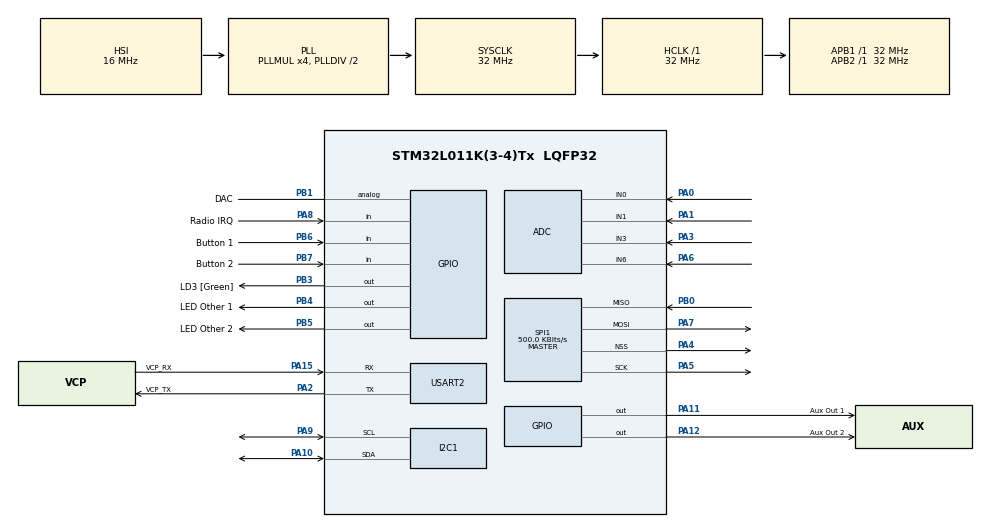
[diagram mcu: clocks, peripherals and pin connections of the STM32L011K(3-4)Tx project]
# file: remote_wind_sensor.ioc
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Mcu.Family=STM32L0
PA6.Mode=IN6
SPI1.VirtualType=VM_MASTER
PA14.GPIO_Label=TCK
PB6.GPIO_Label=Button 1
RCC.SYSCLKSource=RCC_SYSCLKSOURCE_PLLCLK
ProjectManager.StackSize=0x400
PA15.GPIO_Label=VCP_RX
PA12.Signal=GPIO_Output
PA4.Mode=NSS_Signal_Hard_Output
SPI1.Direction=SPI_DIRECTION_2LINES
RCC.HCLKFreq_Value=32000000
RCC.APB2TimFreq_Value=32000000
PB6.Signal=GPIO_Input
SPI1.CalculateBaudRate=500.0 KBits/s
RCC.AHBFreq_Value=32000000
RCC.HSE_VALUE=8000000
USART2.VirtualMode-Asynchronous=VM_ASYNC
PA15.Mode=Asynchronous
RCC.PLLMUL=RCC_PLLMUL_4
PA0-CK_IN.Signal=ADC_IN0
PC14-OSC32_IN.Mode=LSE-External-Oscillator
PA14.Mode=Serial_Wire
PB1.GPIO_Label=DAC
PB7.Signal=GPIO_Input
PA8.Signal=GPIO_Input
SPI1.VirtualNSS=VM_NSSHARD
PB7.GPIO_Label=Button 2
Mcu.Package=LQFP32
PB1.Signal=GPIO_Analog
PA6.Signal=ADC_IN6
PA2.GPIO_Label=VCP_TX
PA10.Signal=I2C1_SDA
PA15.Signal=USART2_RX
PB5.GPIO_Label=LED Other 2
RCC.APB1TimFreq_Value=32000000
SPI1.BaudRatePrescaler=SPI_BAUDRATEPRESCALER_64
RCC.HSI48_VALUE=48000000
PB4.Signal=GPIO_Output
PA3.Signal=ADC_IN3
PA5.Mode=Full_Duplex_Master
PB3.GPIO_Label=LD3 [Green]
RCC.MSI_VALUE=2097000
PC15-OSC32_OUT.Mode=LSE-External-Oscillator
PA7.Mode=Full_Duplex_Master
PA10.Mode=I2C
PA0-CK_IN.Mode=IN0
PA11.GPIO_Label=Aux Out 1
PC14-OSC32_IN.Signal=RCC_OSC32_IN
ADC.ClockPrescaler=ADC_CLOCK_ASYNC_DIV2
PA12.GPIO_Label=Aux Out 2
PA13.Signal=SYS_SWDIO
PA3.Mode=IN3
RCC.HSI16_VALUE=16000000
PA9.Mode=I2C
PA8.GPIO_Label=Radio IRQ
ProjectManager.TargetToolchain=Makefile
PA9.Signal=I2C1_SCL
I2C1.Timing=0x00707CBB
PC15-OSC32_OUT.Signal=RCC_OSC32_OUT
PA1.Signal=ADC_IN1
PA5.Signal=SPI1_SCK
PB0.Mode=Full_Duplex_Master
board=NUCLEO-L011K4
RCC.VCOOutputFreq_Value=64000000
RCC.APB2Freq_Value=32000000
PA1.Mode=IN1
PB4.GPIO_Label=LED Other 1
SPI1.Mode=SPI_MODE_MASTER
PA13.Mode=Serial_Wire
Mcu.Name=STM32L011K(3-4)Tx
PA13.GPIO_Label=TMS
PA2.Signal=USART2_TX
PB3.Signal=GPIO_Output
PA4.Signal=SPI1_NSS
RCC.SYSCLKFreq_VALUE=32000000
PB5.Signal=GPIO_Output
PA11.Signal=GPIO_Output
PA14.Signal=SYS_SWCLK
ProjectManager.HeapSize=0x200
RCC.HSI_VALUE=16000000
PA2.Mode=Asynchronous
RCC.APB1Freq_Value=32000000
PB0.Signal=SPI1_MISO
PA7.Signal=SPI1_MOSI

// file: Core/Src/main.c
/* USER CODE BEGIN Header */
/**
  ******************************************************************************
  * @file           : main.c
  * @brief          : Main program body
  ******************************************************************************
  * @attention
  *
  * <h2><center>&copy; Copyright (c) 2020 STMicroelectronics.
  * All rights reserved.</center></h2>
  *
  * This software component is licensed by ST under BSD 3-Clause license,
  * the "License"; You may not use this file except in compliance with the
  * License. You may obtain a copy of the License at:
  *                        opensource.org/licenses/BSD-3-Clause
  *
  ******************************************************************************
  */
/* USER CODE END Header */
#include "main.h"

/* USER CODE BEGIN Includes */
#include "nrf24l01.h"
/* USER CODE END Includes */

ADC_HandleTypeDef hadc;

I2C_HandleTypeDef hi2c1;

SPI_HandleTypeDef hspi1;

UART_HandleTypeDef huart2;

void SystemClock_Config(void);
static void MX_GPIO_Init(void);
static void MX_ADC_Init(void);
static void MX_I2C1_Init(void);
static void MX_SPI1_Init(void);
static void MX_USART2_UART_Init(void);

void uint16_to_hex(uint8_t dest[], uint16_t value)
{
  uint8_t HEX_DIGITS[] = "0123456789abcdef";
  dest[3] = HEX_DIGITS[(value & 0x000F) >> 0];
  dest[2] = HEX_DIGITS[(value & 0x00F0) >> 4];
  dest[1] = HEX_DIGITS[(value & 0x0F00) >> 8];
  dest[0] = HEX_DIGITS[(value & 0xF000) >> 12];
}

int main(void)
{

  /* MCU Configuration--------------------------------------------------------*/

  /* Reset of all peripherals, Initializes the Flash interface and the Systick. */
  HAL_Init();

  /* Configure the system clock */
  SystemClock_Config();

  /* Initialize all configured peripherals */
  MX_GPIO_Init();
  MX_ADC_Init();
  MX_I2C1_Init();
  MX_SPI1_Init();
  MX_USART2_UART_Init();
  /* USER CODE BEGIN 2 */

  // ADC calibration seems to reduce the noise by several bits
  if (HAL_ADCEx_Calibration_Start(&hadc, ADC_SINGLE_ENDED) != HAL_OK)
  {
    /* Calibration Error */
    Error_Handler();
  }

  // Initialize the radio driver
  // Todo: would be good to break all these initialization values out into a struct or something
  nRF24_Init(&hspi1, GPIOA, Aux_Out_1_Pin, GPIOA, Radio_NSS_Pin);

  uint8_t check_result = nRF24_Check();
  if (check_result == 1) {
    HAL_UART_Transmit(&huart2, (uint8_t *)"radio good\n", 11, 1000);
  } else {
    HAL_UART_Transmit(&huart2, (uint8_t *)"radio bad\n", 10, 1000);
  }

  nRF24_Start();

  // The transmitter sends a 5-byte packets to the address '0xE7 0x1C 0xE3' without Auto-ACK (ShockBurst disabled)
  // Enable ShockBurst (which includes ack packets) for all RX pipes
  nRF24_EnableAA(0xFF);
  // Set RF channel
  nRF24_SetRFChannel(115);
  // Set data rate
  nRF24_SetDataRate(nRF24_DR_1Mbps);
  // Set CRC scheme
  nRF24_SetCRCScheme(nRF24_CRC_2byte);
  // Set address width, its common for all pipes (RX and TX)
  nRF24_SetAddrWidth(5);
  // Configure TX PIPE
  static const uint8_t nRF24_ADDR[] = { 0x01, 0x01, 0x01, 0x01, 0x01 };
  nRF24_SetAddr(nRF24_PIPETX, nRF24_ADDR);
  // Pipe 0 must be configured the same address as TX to receive the ack packet
  nRF24_SetAddr(nRF24_PIPE0, nRF24_ADDR);

  // Set TX power (maximum)
  nRF24_SetTXPower(nRF24_TXPWR_0dBm);
  // Set operational mode (PTX == transmitter)
  nRF24_SetOperationalMode(nRF24_MODE_TX);
  // Clear any pending IRQ flags
  nRF24_ClearIRQFlags();
  // Wake the transceiver
  nRF24_SetPowerMode(nRF24_PWR_UP);

  /* USER CODE END 2 */

  /* Infinite loop */
  /* USER CODE BEGIN WHILE */
  // Counter to generate dummy data
  int j=0;
  while (1)
  {
    /* USER CODE END WHILE */

    HAL_ADC_Start(&hadc);
    HAL_ADC_PollForConversion(&hadc, 1000);
    uint16_t adc_value = HAL_ADC_GetValue(&hadc);

    uint8_t adc_value_as_hex[4];
    uint16_to_hex(adc_value_as_hex, adc_value);

    HAL_UART_Transmit(&huart2, adc_value_as_hex, sizeof(adc_value_as_hex), 1000);
    HAL_UART_Transmit(&huart2, (uint8_t *) "\n", 1, 1000);

    // Prepare data packet with dummy data
    uint8_t nRF24_payload[32];
    int payload_length = 5;
    for (int payload_byte_index = 0;
      payload_byte_index < payload_length;
      payload_byte_index++) {
        nRF24_payload[payload_byte_index] = j++;
        if (j > 0x000000FF) j = 0;
    }

    // Transmit a packet
    nRF24_TXResult transmit_result = nRF24_TransmitPacket(nRF24_payload, payload_length);

    switch (transmit_result) {
        case nRF24_TX_SUCCESS:
            HAL_UART_Transmit(&huart2, (uint8_t *) "OK\n", 3, 1000);
            break;
        case nRF24_TX_TIMEOUT:
            HAL_UART_Transmit(&huart2, (uint8_t *) "TIMEOUT\n", 8, 1000);
            break;
        case nRF24_TX_MAXRT:
            HAL_UART_Transmit(&huart2, (uint8_t *) "MAX RETRANSMIT\n", 15, 1000);
            break;
        default:
            HAL_UART_Transmit(&huart2, (uint8_t *) "ERROR\n", 6, 1000);
            break;
    }

    HAL_GPIO_TogglePin(LD3_GPIO_Port, LD3_Pin);

    HAL_Delay(500);

  }
}

void SystemClock_Config(void)
{
  RCC_OscInitTypeDef RCC_OscInitStruct = {0};
  RCC_ClkInitTypeDef RCC_ClkInitStruct = {0};
  RCC_PeriphCLKInitTypeDef PeriphClkInit = {0};

  /** Configure the main internal regulator output voltage
  */
  __HAL_PWR_VOLTAGESCALING_CONFIG(PWR_REGULATOR_VOLTAGE_SCALE1);
  /** Initializes the RCC Oscillators according to the specified parameters
  * in the RCC_OscInitTypeDef structure.
  */
  RCC_OscInitStruct.OscillatorType = RCC_OSCILLATORTYPE_HSI;
  RCC_OscInitStruct.HSIState = RCC_HSI_ON;
  RCC_OscInitStruct.HSICalibrationValue = RCC_HSICALIBRATION_DEFAULT;
  RCC_OscInitStruct.PLL.PLLState = RCC_PLL_ON;
  RCC_OscInitStruct.PLL.PLLSource = RCC_PLLSOURCE_HSI;
  RCC_OscInitStruct.PLL.PLLMUL = RCC_PLLMUL_4;
  RCC_OscInitStruct.PLL.PLLDIV = RCC_PLLDIV_2;
  if (HAL_RCC_OscConfig(&RCC_OscInitStruct) != HAL_OK)
  {
    Error_Handler();
  }
  /** Initializes the CPU, AHB and APB buses clocks
  */
  RCC_ClkInitStruct.ClockType = RCC_CLOCKTYPE_HCLK|RCC_CLOCKTYPE_SYSCLK
                              |RCC_CLOCKTYPE_PCLK1|RCC_CLOCKTYPE_PCLK2;
  RCC_ClkInitStruct.SYSCLKSource = RCC_SYSCLKSOURCE_PLLCLK;
  RCC_ClkInitStruct.AHBCLKDivider = RCC_SYSCLK_DIV1;
  RCC_ClkInitStruct.APB1CLKDivider = RCC_HCLK_DIV1;
  RCC_ClkInitStruct.APB2CLKDivider = RCC_HCLK_DIV1;

  if (HAL_RCC_ClockConfig(&RCC_ClkInitStruct, FLASH_LATENCY_1) != HAL_OK)
  {
    Error_Handler();
  }
  PeriphClkInit.PeriphClockSelection = RCC_PERIPHCLK_USART2|RCC_PERIPHCLK_I2C1;
  PeriphClkInit.Usart2ClockSelection = RCC_USART2CLKSOURCE_PCLK1;
  PeriphClkInit.I2c1ClockSelection = RCC_I2C1CLKSOURCE_PCLK1;
  if (HAL_RCCEx_PeriphCLKConfig(&PeriphClkInit) != HAL_OK)
  {
    Error_Handler();
  }
}

static void MX_ADC_Init(void)
{

  ADC_ChannelConfTypeDef sConfig = {0};

  /** Configure the global features of the ADC (Clock, Resolution, Data Alignment and number of conversion)
  */
  hadc.Instance = ADC1;
  hadc.Init.OversamplingMode = DISABLE;
  hadc.Init.ClockPrescaler = ADC_CLOCK_ASYNC_DIV2;
  hadc.Init.Resolution = ADC_RESOLUTION_12B;
  hadc.Init.SamplingTime = ADC_SAMPLETIME_1CYCLE_5;
  hadc.Init.ScanConvMode = ADC_SCAN_DIRECTION_FORWARD;
  hadc.Init.DataAlign = ADC_DATAALIGN_RIGHT;
  hadc.Init.ContinuousConvMode = DISABLE;
  hadc.Init.DiscontinuousConvMode = DISABLE;
  hadc.Init.ExternalTrigConvEdge = ADC_EXTERNALTRIGCONVEDGE_NONE;
  hadc.Init.ExternalTrigConv = ADC_SOFTWARE_START;
  hadc.Init.DMAContinuousRequests = DISABLE;
  hadc.Init.EOCSelection = ADC_EOC_SINGLE_CONV;
  hadc.Init.Overrun = ADC_OVR_DATA_PRESERVED;
  hadc.Init.LowPowerAutoWait = DISABLE;
  hadc.Init.LowPowerFrequencyMode = DISABLE;
  hadc.Init.LowPowerAutoPowerOff = DISABLE;
  if (HAL_ADC_Init(&hadc) != HAL_OK)
  {
    Error_Handler();
  }
  /** Configure for the selected ADC regular channel to be converted.
  */
  sConfig.Channel = ADC_CHANNEL_0;
  sConfig.Rank = ADC_RANK_CHANNEL_NUMBER;
  if (HAL_ADC_ConfigChannel(&hadc, &sConfig) != HAL_OK)
  {
    Error_Handler();
  }
  /** Configure for the selected ADC regular channel to be converted.
  */
  sConfig.Channel = ADC_CHANNEL_1;
  if (HAL_ADC_ConfigChannel(&hadc, &sConfig) != HAL_OK)
  {
    Error_Handler();
  }
  /** Configure for the selected ADC regular channel to be converted.
  */
  sConfig.Channel = ADC_CHANNEL_3;
  if (HAL_ADC_ConfigChannel(&hadc, &sConfig) != HAL_OK)
  {
    Error_Handler();
  }
  /** Configure for the selected ADC regular channel to be converted.
  */
  sConfig.Channel = ADC_CHANNEL_6;
  if (HAL_ADC_ConfigChannel(&hadc, &sConfig) != HAL_OK)
  {
    Error_Handler();
  }

}

static void MX_I2C1_Init(void)
{

  hi2c1.Instance = I2C1;
  hi2c1.Init.Timing = 0x00707CBB;
  hi2c1.Init.OwnAddress1 = 0;
  hi2c1.Init.AddressingMode = I2C_ADDRESSINGMODE_7BIT;
  hi2c1.Init.DualAddressMode = I2C_DUALADDRESS_DISABLE;
  hi2c1.Init.OwnAddress2 = 0;
  hi2c1.Init.OwnAddress2Masks = I2C_OA2_NOMASK;
  hi2c1.Init.GeneralCallMode = I2C_GENERALCALL_DISABLE;
  hi2c1.Init.NoStretchMode = I2C_NOSTRETCH_DISABLE;
  if (HAL_I2C_Init(&hi2c1) != HAL_OK)
  {
    Error_Handler();
  }
  /** Configure Analogue filter
  */
  if (HAL_I2CEx_ConfigAnalogFilter(&hi2c1, I2C_ANALOGFILTER_ENABLE) != HAL_OK)
  {
    Error_Handler();
  }
  /** Configure Digital filter
  */
  if (HAL_I2CEx_ConfigDigitalFilter(&hi2c1, 0) != HAL_OK)
  {
    Error_Handler();
  }

}

static void MX_SPI1_Init(void)
{

  /* SPI1 parameter configuration*/
  hspi1.Instance = SPI1;
  hspi1.Init.Mode = SPI_MODE_MASTER;
  hspi1.Init.Direction = SPI_DIRECTION_2LINES;
  hspi1.Init.DataSize = SPI_DATASIZE_8BIT;
  hspi1.Init.CLKPolarity = SPI_POLARITY_LOW;
  hspi1.Init.CLKPhase = SPI_PHASE_1EDGE;
  hspi1.Init.NSS = SPI_NSS_SOFT;
  hspi1.Init.BaudRatePrescaler = SPI_BAUDRATEPRESCALER_64;
  hspi1.Init.FirstBit = SPI_FIRSTBIT_MSB;
  hspi1.Init.TIMode = SPI_TIMODE_DISABLE;
  hspi1.Init.CRCCalculation = SPI_CRCCALCULATION_DISABLE;
  hspi1.Init.CRCPolynomial = 7;
  if (HAL_SPI_Init(&hspi1) != HAL_OK)
  {
    Error_Handler();
  }

}

static void MX_USART2_UART_Init(void)
{

  huart2.Instance = USART2;
  huart2.Init.BaudRate = 115200;
  huart2.Init.WordLength = UART_WORDLENGTH_8B;
  huart2.Init.StopBits = UART_STOPBITS_1;
  huart2.Init.Parity = UART_PARITY_NONE;
  huart2.Init.Mode = UART_MODE_TX_RX;
  huart2.Init.HwFlowCtl = UART_HWCONTROL_NONE;
  huart2.Init.OverSampling = UART_OVERSAMPLING_16;
  huart2.Init.OneBitSampling = UART_ONE_BIT_SAMPLE_DISABLE;
  huart2.AdvancedInit.AdvFeatureInit = UART_ADVFEATURE_NO_INIT;
  if (HAL_UART_Init(&huart2) != HAL_OK)
  {
    Error_Handler();
  }

}

static void MX_GPIO_Init(void)
{
  GPIO_InitTypeDef GPIO_InitStruct = {0};

  /* GPIO Ports Clock Enable */
  __HAL_RCC_GPIOC_CLK_ENABLE();
  __HAL_RCC_GPIOA_CLK_ENABLE();
  __HAL_RCC_GPIOB_CLK_ENABLE();

  /*Configure GPIO pin Output Level */
  HAL_GPIO_WritePin(GPIOA, Radio_NSS_Pin|Aux_Out_1_Pin|Aux_Out_2_Pin, GPIO_PIN_RESET);

  /*Configure GPIO pin Output Level */
  HAL_GPIO_WritePin(GPIOB, LD3_Pin|LED_Other_1_Pin|LED_Other_2_Pin, GPIO_PIN_RESET);

  /*Configure GPIO pins : Radio_NSS_Pin Aux_Out_1_Pin Aux_Out_2_Pin */
  GPIO_InitStruct.Pin = Radio_NSS_Pin|Aux_Out_1_Pin|Aux_Out_2_Pin;
  GPIO_InitStruct.Mode = GPIO_MODE_OUTPUT_PP;
  GPIO_InitStruct.Pull = GPIO_NOPULL;
  GPIO_InitStruct.Speed = GPIO_SPEED_FREQ_LOW;
  HAL_GPIO_Init(GPIOA, &GPIO_InitStruct);

  /*Configure GPIO pin : DAC_Pin */
  GPIO_InitStruct.Pin = DAC_Pin;
  GPIO_InitStruct.Mode = GPIO_MODE_ANALOG;
  GPIO_InitStruct.Pull = GPIO_NOPULL;
  HAL_GPIO_Init(DAC_GPIO_Port, &GPIO_InitStruct);

  /*Configure GPIO pin : Radio_IRQ_Pin */
  GPIO_InitStruct.Pin = Radio_IRQ_Pin;
  GPIO_InitStruct.Mode = GPIO_MODE_INPUT;
  GPIO_InitStruct.Pull = GPIO_NOPULL;
  HAL_GPIO_Init(Radio_IRQ_GPIO_Port, &GPIO_InitStruct);

  /*Configure GPIO pins : LD3_Pin LED_Other_1_Pin LED_Other_2_Pin */
  GPIO_InitStruct.Pin = LD3_Pin|LED_Other_1_Pin|LED_Other_2_Pin;
  GPIO_InitStruct.Mode = GPIO_MODE_OUTPUT_PP;
  GPIO_InitStruct.Pull = GPIO_NOPULL;
  GPIO_InitStruct.Speed = GPIO_SPEED_FREQ_LOW;
  HAL_GPIO_Init(GPIOB, &GPIO_InitStruct);

  /*Configure GPIO pins : Button_1_Pin Button_2_Pin */
  GPIO_InitStruct.Pin = Button_1_Pin|Button_2_Pin;
  GPIO_InitStruct.Mode = GPIO_MODE_INPUT;
  GPIO_InitStruct.Pull = GPIO_NOPULL;
  HAL_GPIO_Init(GPIOB, &GPIO_InitStruct);

}

void Error_Handler(void)
{
}

/************************ (C) COPYRIGHT STMicroelectronics *****END OF FILE****/
